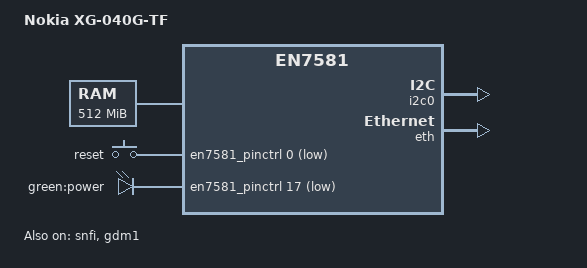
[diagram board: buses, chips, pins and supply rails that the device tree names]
// SPDX-License-Identifier: (GPL-2.0-only OR BSD-2-Clause)
/dts-v1/;

#include <dt-bindings/gpio/gpio.h>
#include <dt-bindings/input/input.h>
#include <dt-bindings/leds/common.h>
#include "en7581.dtsi"

/ {
	model = "Nokia XG-040G-TF";
	compatible = "nokia,xg-040g-tf-ubi", "airoha,an7581",
		     "airoha,en7581";

	aliases {
		serial0 = &uart1;
	};

	chosen {
		stdout-path = "serial0:115200n8";
	};

	memory@80000000 {
		device_type = "memory";
		reg = <0x0 0x80000000 0x0 0x20000000>;
	};

	keys {
		compatible = "gpio-keys";

		key-reset {
			label = "reset";
			linux,code = <KEY_RESTART>;
			gpios = <&en7581_pinctrl 0 GPIO_ACTIVE_LOW>;
		};
	};

	leds {
		compatible = "gpio-leds";

		led-power-green {
			label = "green:power";
			gpios = <&en7581_pinctrl 17 GPIO_ACTIVE_LOW>;
		};
	};
};

&en7581_pinctrl {
	gpio-ranges = <&en7581_pinctrl 0 13 50>;
};

&snfi {
	status = "okay";
};

&spi_nand {
	partitions {
		compatible = "fixed-partitions";
		#address-cells = <1>;
		#size-cells = <1>;

		partition@0 {
			label = "bl2";
			reg = <0x0 0x20000>;
		};

		partition@20000 {
			label = "ubi";
			reg = <0x20000 0xffe0000>;
		};
	};
};

&i2c0 {
	status = "okay";
};

&eth {
	status = "okay";
};

&gdm1 {
	status = "okay";
};
